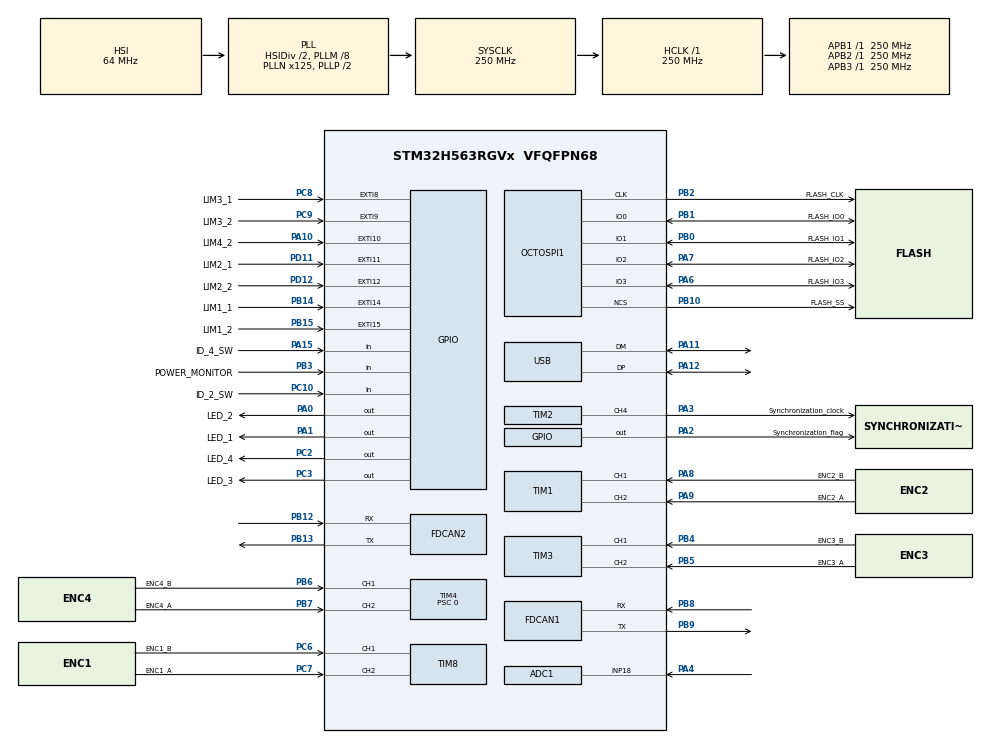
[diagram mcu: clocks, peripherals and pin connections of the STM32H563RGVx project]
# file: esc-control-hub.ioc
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ADC1.Channel-0\#ChannelRegularConversion=ADC_CHANNEL_18
ADC1.MonitoredBy-0\#ChannelRegularConversion=__NULL
ADC1.NbrOfConversionFlag=1
ADC1.OffsetNumber-0\#ChannelRegularConversion=ADC_OFFSET_NONE
ADC1.Rank-0\#ChannelRegularConversion=1
ADC1.SamplingTime-0\#ChannelRegularConversion=ADC_SAMPLETIME_2CYCLES_5
ADC1.master=1
BOOTPATH.BootPathName=LEGACY
BOOTPATH.UserSelectedBootPath=LEGACY
CORTEX_M33_NS.userName=CORTEX_M33
DCACHE1.DCACHE_Read_Burst_Type=DCACHE_READ_BURST_INCR
FDCAN1.CalculateBaudRateNominal=1000000
FDCAN1.CalculateTimeBitNominal=1000
FDCAN1.CalculateTimeQuantumNominal=100.0
FDCAN1.ExtFiltersNbr=4
FDCAN1.FrameFormat=FDCAN_FRAME_FD_NO_BRS
FDCAN1.NominalPrescaler=8
FDCAN1.NominalTimeSeg1=7
FDCAN1.NominalTimeSeg2=2
FDCAN1.StdFiltersNbr=4
FDCAN2.CalculateBaudRateNominal=1000000
FDCAN2.CalculateTimeBitNominal=1000
FDCAN2.CalculateTimeQuantumNominal=100.0
FDCAN2.ClockDivider=FDCAN_CLOCK_DIV1
FDCAN2.ExtFiltersNbr=4
FDCAN2.NominalPrescaler=8
FDCAN2.NominalTimeSeg1=7
FDCAN2.NominalTimeSeg2=2
FDCAN2.StdFiltersNbr=4
Mcu.Family=STM32H5
Mcu.Name=STM32H563RGVx
Mcu.Package=VFQFPN68
NVIC.EXTI10_IRQn=true\:0\:0\:false\:false\:true\:true\:true\:true
NVIC.EXTI11_IRQn=true\:0\:0\:false\:false\:true\:true\:true\:true
NVIC.EXTI12_IRQn=true\:0\:0\:false\:false\:true\:true\:true\:true
NVIC.EXTI14_IRQn=true\:0\:0\:false\:false\:true\:true\:true\:true
NVIC.EXTI15_IRQn=true\:0\:0\:false\:false\:true\:true\:true\:true
NVIC.EXTI8_IRQn=true\:0\:0\:false\:false\:true\:true\:true\:true
NVIC.EXTI9_IRQn=true\:0\:0\:false\:false\:true\:true\:true\:true
NVIC.FDCAN1_IT0_IRQn=true\:0\:0\:false\:false\:true\:true\:true\:true
NVIC.FDCAN2_IT0_IRQn=true\:0\:0\:false\:false\:true\:true\:true\:true
NVIC.PriorityGroup=NVIC_PRIORITYGROUP_4
NVIC.RTC_IRQn=true\:0\:0\:false\:false\:true\:true\:true\:true
NVIC.TIM4_IRQn=true\:0\:0\:false\:false\:true\:true\:true\:true
NVIC.TIM6_IRQn=true\:0\:0\:false\:false\:true\:true\:true\:true
PA0.GPIO_Label=LED_2
PA0.Signal=GPIO_Output
PA1.GPIO_Label=LED_1
PA1.Signal=GPIO_Output
PA10.GPIO_Label=LIM4_2
PA10.GPIO_ModeDefaultEXTI=GPIO_MODE_IT_FALLING
PA10.Signal=GPXTI10
PA11.Mode=Device
PA11.Signal=USB_DM
PA12.Mode=Device
PA12.Signal=USB_DP
PA13(JTMS/SWDIO).Mode=Serial_Wire
PA13(JTMS/SWDIO).Signal=DEBUG_JTMS-SWDIO
PA14(JTCK/SWCLK).Mode=Serial_Wire
PA14(JTCK/SWCLK).Signal=DEBUG_JTCK-SWCLK
PA15(JTDI).GPIO_Label=ID_4_SW
PA15(JTDI).Signal=GPIO_Input
PA2.GPIO_Label=Synchronization_flag
PA2.Signal=GPIO_Output
PA3.GPIO_Label=Synchronization_clock
PA3.GPIO_Speed=GPIO_SPEED_FREQ_HIGH
PA3.Signal=S_TIM2_CH4
PA4.Signal=ADCx_INP18
PA6.GPIO_Label=FLASH_IO3
PA6.Mode=OCTOSPI1_IO[3\:0]
PA6.Signal=OCTOSPI1_IO3
PA7.GPIO_Label=FLASH_IO2
PA7.Mode=OCTOSPI1_IO[3\:0]
PA7.Signal=OCTOSPI1_IO2
PA8.GPIO_Label=ENC2_B
PA8.GPIO_Speed=GPIO_SPEED_FREQ_LOW
PA8.Signal=S_TIM1_CH1
PA9.GPIO_Label=ENC2_A
PA9.Signal=S_TIM1_CH2
PB0.GPIO_Label=FLASH_IO1
PB0.Mode=OCTOSPI1_IO[3\:0]
PB0.Signal=OCTOSPI1_IO1
PB1.GPIO_Label=FLASH_IO0
PB1.Mode=OCTOSPI1_IO[3\:0]
PB1.Signal=OCTOSPI1_IO0
PB10.GPIO_Label=FLASH_SS
PB10.Mode=quad_mode
PB10.Signal=OCTOSPI1_NCS
PB12.Mode=FDCAN_Activate
PB12.Signal=FDCAN2_RX
PB13.Mode=FDCAN_Activate
PB13.Signal=FDCAN2_TX
PB14.GPIO_Label=LIM1_1
PB14.GPIO_ModeDefaultEXTI=GPIO_MODE_IT_FALLING
PB14.Signal=GPXTI14
PB15.GPIO_Label=LIM1_2
PB15.GPIO_ModeDefaultEXTI=GPIO_MODE_IT_FALLING
PB15.Signal=GPXTI15
PB2.GPIO_Label=FLASH_CLK
PB2.Mode=quad_mode
PB2.Signal=OCTOSPI1_CLK
PB3(JTDO/TRACESWO).GPIO_Label=POWER_MONITOR
PB3(JTDO/TRACESWO).Signal=GPIO_Input
PB4(NJTRST).GPIO_Label=ENC3_B
PB4(NJTRST).Signal=S_TIM3_CH1
PB5.GPIO_Label=ENC3_A
PB5.Signal=S_TIM3_CH2
PB6.GPIO_Label=ENC4_B
PB6.Signal=S_TIM4_CH1
PB7.GPIO_Label=ENC4_A
PB7.Signal=S_TIM4_CH2
PB8.Mode=FDCAN_Activate
PB8.Signal=FDCAN1_RX
PB9.Mode=FDCAN_Activate
PB9.Signal=FDCAN1_TX
PC10.GPIO_Label=ID_2_SW
PC10.Signal=GPIO_Input
PC2.GPIO_Label=LED_4
PC2.Signal=GPIO_Output
PC3.GPIO_Label=LED_3
PC3.Signal=GPIO_Output
PC6.GPIO_Label=ENC1_B
PC6.Signal=S_TIM8_CH1
PC7.GPIO_Label=ENC1_A
PC7.Signal=S_TIM8_CH2
PC8.GPIO_Label=LIM3_1
PC8.GPIO_ModeDefaultEXTI=GPIO_MODE_IT_FALLING
PC8.Signal=GPXTI8
PC9.GPIO_Label=LIM3_2
PC9.GPIO_ModeDefaultEXTI=GPIO_MODE_IT_FALLING
PC9.Signal=GPXTI9
PD11.GPIO_Label=LIM2_1
PD11.GPIO_ModeDefaultEXTI=GPIO_MODE_IT_FALLING
PD11.Signal=GPXTI11
PD12.GPIO_Label=LIM2_2
PD12.GPIO_ModeDefaultEXTI=GPIO_MODE_IT_FALLING
PD12.Signal=GPXTI12
ProjectManager.HeapSize=0x200
ProjectManager.StackSize=0x400
ProjectManager.TargetToolchain=CMake
RCC.ADCFreq_Value=250000000
RCC.AHBFreq_Value=250000000
RCC.APB1Freq_Value=250000000
RCC.APB1TimFreq_Value=250000000
RCC.APB2Freq_Value=250000000
RCC.APB2TimFreq_Value=250000000
RCC.APB3Freq_Value=250000000
RCC.CSI_VALUE=4000000
RCC.CortexFreq_Value=250000000
RCC.EPOD_VALUE=32000000
RCC.FDCANClockSelection=RCC_FDCANCLKSOURCE_PLL2Q
RCC.HCLKFreq_Value=250000000
RCC.HSE_VALUE=24000000
RCC.HSI48_VALUE=48000000
RCC.HSI_VALUE=64000000
RCC.LSE_VALUE=32768
RCC.LSIRC_VALUE=32000
RCC.OCTOSPIMCLockSelection=RCC_OSPICLKSOURCE_PLL1Q
RCC.PLL2N=40
RCC.PLL3M=8
RCC.PLL3Source=RCC_PLL3_SOURCE_HSI
RCC.PLLM=8
RCC.PLLN=125
RCC.PLLSourceVirtual=RCC_PLL1_SOURCE_HSI
RCC.SYSCLKFreq_VALUE=250000000
RCC.SYSCLKSource=RCC_SYSCLKSOURCE_PLLCLK
RCC.USBFreq_Value=48000000
RCC.VCOOutputFreq_Value=500000000
RTC.WakeUpClock-WakeUp=RTC_WAKEUPCLOCK_CK_SPRE_16BITS
SH.ADCx_INP18.0=ADC1_INP18,IN18-Single-Ended
SH.S_TIM1_CH1.0=TIM1_CH1,Encoder_Interface
SH.S_TIM1_CH2.0=TIM1_CH2,Encoder_Interface
SH.S_TIM2_CH4.0=TIM2_CH4,PWM Generation4 CH4
SH.S_TIM3_CH1.0=TIM3_CH1,Encoder_Interface
SH.S_TIM3_CH2.0=TIM3_CH2,Encoder_Interface
SH.S_TIM4_CH1.0=TIM4_CH1,Encoder_Interface
SH.S_TIM4_CH2.0=TIM4_CH2,Encoder_Interface
SH.S_TIM8_CH1.0=TIM8_CH1,Encoder_Interface
SH.S_TIM8_CH2.0=TIM8_CH2,Encoder_Interface
TIM2.Channel-PWM\ Generation4\ CH4=TIM_CHANNEL_4
TIM2.PeriodNoDither=100
TIM2.Prescaler=250
TIM3.EncoderMode=TIM_ENCODERMODE_TI12
TIM4.PeriodNoDither=100
TIM4.Prescaler=0
TIM6.PeriodNoDither=1000
TIM6.Prescaler=250
TIM8.EncoderMode=TIM_ENCODERMODE_TI12
TIM8.IC1Filter=15
USB.Sof_enable-Device=ENABLE
USB.VirtualMode=Device_Only
USB.bulk_doublebuffer_enable=ENABLE
USB.iso_singlebuffer_enable=ENABLE
VP_BOOTPATH_VS_BOOTPATH.Mode=BP_Activate
VP_CORTEX_M33_NS_VS_Hclk.Mode=Hclk_Mode
VP_DCACHE1_VS_DCACHE.Mode=DCACHE_Activate
VP_ICACHE_VS_ICACHE.Mode=DefaultMode
VP_MEMORYMAP_VS_MEMORYMAP.Mode=CurAppReg
VP_PWR_VS_LPOM.Mode=PowerOptimisation
VP_PWR_VS_SECSignals.Mode=Security/Privilege
VP_RTC_VS_RTC_Activate.Mode=RTC_Enabled
VP_RTC_VS_RTC_WakeUp_intern.Mode=WakeUp
VP_TIM6_VS_ClockSourceINT.Mode=Enable_Timer
board=custom

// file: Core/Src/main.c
/* USER CODE BEGIN Header */
/**
 ******************************************************************************
 * @file           : main.c
 * @brief          : Main program body
 ******************************************************************************
 * @attention
 *
 * Copyright (c) 2026 STMicroelectronics.
 * All rights reserved.
 *
 * This software is licensed under terms that can be found in the LICENSE file
 * in the root directory of this software component.
 * If no LICENSE file comes with this software, it is provided AS-IS.
 *
 ******************************************************************************
 */
/* USER CODE END Header */
#include "main.h"
#include "adc.h"
#include "dcache.h"
#include "fdcan.h"
#include "icache.h"
#include "octospi.h"
#include "rtc.h"
#include "tim.h"
#include "usb.h"
#include "gpio.h"

/* USER CODE BEGIN Includes */
#include "encoder/encoder.hpp"
/* USER CODE END Includes */

void SystemClock_Config(void);
void PeriphCommonClock_Config(void);

int main(void)
{

  /* MCU Configuration--------------------------------------------------------*/

  /* Reset of all peripherals, Initializes the Flash interface and the Systick. */
  HAL_Init();

  /* Configure the system clock */
  SystemClock_Config();

  /* Configure the peripherals common clocks */
  PeriphCommonClock_Config();

  /* Initialize all configured peripherals */
  MX_GPIO_Init();
  MX_FDCAN1_Init();
  MX_FDCAN2_Init();
  MX_OCTOSPI1_Init();
  MX_RTC_Init();
  MX_TIM1_Init();
  MX_TIM3_Init();
  MX_TIM4_Init();
  MX_USB_PCD_Init();
  MX_TIM8_Init();
  MX_TIM2_Init();
  MX_TIM6_Init();
  MX_ICACHE_Init();
  MX_DCACHE1_Init();
  MX_ADC1_Init();
  /* USER CODE BEGIN 2 */
    setup();
  /* USER CODE END 2 */

  /* Infinite loop */
    while (1) {

    /* USER CODE BEGIN 3 */
        loop();
    }
  /* USER CODE END 3 */
}

void SystemClock_Config(void)
{
  RCC_OscInitTypeDef RCC_OscInitStruct = {0};
  RCC_ClkInitTypeDef RCC_ClkInitStruct = {0};

  /** Configure the main internal regulator output voltage
  */
  __HAL_PWR_VOLTAGESCALING_CONFIG(PWR_REGULATOR_VOLTAGE_SCALE0);

  while(!__HAL_PWR_GET_FLAG(PWR_FLAG_VOSRDY)) {}

  /** Initializes the RCC Oscillators according to the specified parameters
  * in the RCC_OscInitTypeDef structure.
  */
  RCC_OscInitStruct.OscillatorType = RCC_OSCILLATORTYPE_HSI48|RCC_OSCILLATORTYPE_HSI
                              |RCC_OSCILLATORTYPE_LSI|RCC_OSCILLATORTYPE_CSI;
  RCC_OscInitStruct.HSIState = RCC_HSI_ON;
  RCC_OscInitStruct.HSIDiv = RCC_HSI_DIV2;
  RCC_OscInitStruct.HSICalibrationValue = RCC_HSICALIBRATION_DEFAULT;
  RCC_OscInitStruct.LSIState = RCC_LSI_ON;
  RCC_OscInitStruct.HSI48State = RCC_HSI48_ON;
  RCC_OscInitStruct.CSIState = RCC_CSI_ON;
  RCC_OscInitStruct.CSICalibrationValue = RCC_CSICALIBRATION_DEFAULT;
  RCC_OscInitStruct.PLL.PLLState = RCC_PLL_ON;
  RCC_OscInitStruct.PLL.PLLSource = RCC_PLL1_SOURCE_HSI;
  RCC_OscInitStruct.PLL.PLLM = 8;
  RCC_OscInitStruct.PLL.PLLN = 125;
  RCC_OscInitStruct.PLL.PLLP = 2;
  RCC_OscInitStruct.PLL.PLLQ = 2;
  RCC_OscInitStruct.PLL.PLLR = 2;
  RCC_OscInitStruct.PLL.PLLRGE = RCC_PLL1_VCIRANGE_2;
  RCC_OscInitStruct.PLL.PLLVCOSEL = RCC_PLL1_VCORANGE_WIDE;
  RCC_OscInitStruct.PLL.PLLFRACN = 0;
  if (HAL_RCC_OscConfig(&RCC_OscInitStruct) != HAL_OK)
  {
    Error_Handler();
  }

  /** Initializes the CPU, AHB and APB buses clocks
  */
  RCC_ClkInitStruct.ClockType = RCC_CLOCKTYPE_HCLK|RCC_CLOCKTYPE_SYSCLK
                              |RCC_CLOCKTYPE_PCLK1|RCC_CLOCKTYPE_PCLK2
                              |RCC_CLOCKTYPE_PCLK3;
  RCC_ClkInitStruct.SYSCLKSource = RCC_SYSCLKSOURCE_PLLCLK;
  RCC_ClkInitStruct.AHBCLKDivider = RCC_SYSCLK_DIV1;
  RCC_ClkInitStruct.APB1CLKDivider = RCC_HCLK_DIV1;
  RCC_ClkInitStruct.APB2CLKDivider = RCC_HCLK_DIV1;
  RCC_ClkInitStruct.APB3CLKDivider = RCC_HCLK_DIV1;

  if (HAL_RCC_ClockConfig(&RCC_ClkInitStruct, FLASH_LATENCY_5) != HAL_OK)
  {
    Error_Handler();
  }

  /** Configure the programming delay
  */
  __HAL_FLASH_SET_PROGRAM_DELAY(FLASH_PROGRAMMING_DELAY_2);
}

void PeriphCommonClock_Config(void)
{
  RCC_PeriphCLKInitTypeDef PeriphClkInitStruct = {0};

  /** Initializes the peripherals clock
  */
  PeriphClkInitStruct.PeriphClockSelection = RCC_PERIPHCLK_ADCDAC|RCC_PERIPHCLK_FDCAN;
  PeriphClkInitStruct.PLL2.PLL2Source = RCC_PLL2_SOURCE_CSI;
  PeriphClkInitStruct.PLL2.PLL2M = 1;
  PeriphClkInitStruct.PLL2.PLL2N = 40;
  PeriphClkInitStruct.PLL2.PLL2P = 2;
  PeriphClkInitStruct.PLL2.PLL2Q = 2;
  PeriphClkInitStruct.PLL2.PLL2R = 2;
  PeriphClkInitStruct.PLL2.PLL2RGE = RCC_PLL2_VCIRANGE_2;
  PeriphClkInitStruct.PLL2.PLL2VCOSEL = RCC_PLL2_VCORANGE_WIDE;
  PeriphClkInitStruct.PLL2.PLL2FRACN = 0;
  PeriphClkInitStruct.PLL2.PLL2ClockOut = RCC_PLL2_DIVQ;
  PeriphClkInitStruct.FdcanClockSelection = RCC_FDCANCLKSOURCE_PLL2Q;
  PeriphClkInitStruct.OspiClockSelection = RCC_OSPICLKSOURCE_PLL1Q;
  if (HAL_RCCEx_PeriphCLKConfig(&PeriphClkInitStruct) != HAL_OK)
  {
    Error_Handler();
  }
}

void Error_Handler(void)
{
    __disable_irq();
    while (1) {
    }
}
